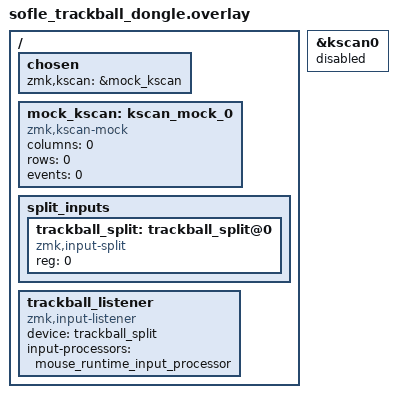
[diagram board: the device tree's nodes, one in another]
/*
 * Copyright (c) 2020 ZMK Contributors
 *
 * SPDX-License-Identifier: MIT
 */
#include <dt-bindings/zmk/input_transform.h>
#include <input/processors.dtsi>
#include <input/processors/runtime-input-processor.dtsi>
#include "sofle_trackball.dtsi"

/ {
    chosen {
        zmk,kscan = &mock_kscan;
        /delete-property/ zmk,underglow;
        /delete-property/ zmk,backlight;
    };

    mock_kscan: kscan_mock_0 {
        compatible = "zmk,kscan-mock";
        columns = <0>;
        rows = <0>;
        events = <0>;
    };

    split_inputs {
        #address-cells = <1>;
        #size-cells = <0>;
        trackball_split: trackball_split@0 {
            compatible = "zmk,input-split";
            reg = <0>;
        };
    };

    trackball_listener {
        compatible = "zmk,input-listener";
        device = <&trackball_split>;
        input-processors = <&mouse_runtime_input_processor>;
    };
};

&kscan0 {
    status = "disabled";
};
